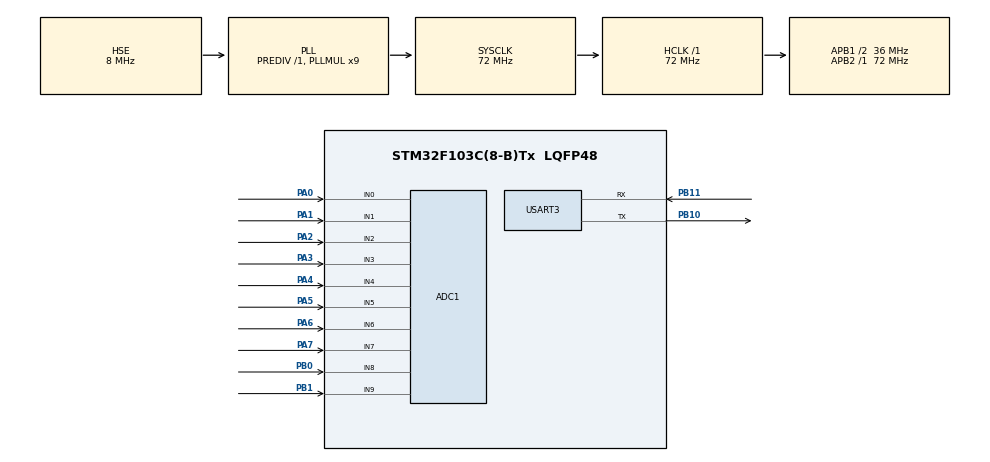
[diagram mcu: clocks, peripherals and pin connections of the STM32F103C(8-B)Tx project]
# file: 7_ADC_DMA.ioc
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Mcu.Family=STM32F1
NVIC.ADC1_2_IRQn=true\:0\:0\:false\:false\:true\:true\:true
ADC1.ContinuousConvMode=DISABLE
PB10.Mode=Asynchronous
SH.ADCx_IN2.0=ADC1_IN2,IN2
ADC1.SamplingTime-6\#ChannelRegularConversion=ADC_SAMPLETIME_1CYCLE_5
PB11.Signal=USART3_RX
ADC1.Channel-8\#ChannelRegularConversion=ADC_CHANNEL_8
RCC.SYSCLKSource=RCC_SYSCLKSOURCE_PLLCLK
ProjectManager.StackSize=0x400
PD1-OSC_OUT.Signal=RCC_OSC_OUT
ADC1.Channel-5\#ChannelRegularConversion=ADC_CHANNEL_5
ADC1.Channel-3\#ChannelRegularConversion=ADC_CHANNEL_3
RCC.HCLKFreq_Value=72000000
SH.ADCx_IN3.0=ADC1_IN3,IN3
RCC.APB2TimFreq_Value=72000000
Dma.ADC1.0.Direction=DMA_PERIPH_TO_MEMORY
ADC1.Channel-2\#ChannelRegularConversion=ADC_CHANNEL_2
Dma.ADC1.0.MemDataAlignment=DMA_MDATAALIGN_HALFWORD
RCC.AHBFreq_Value=72000000
ADC1.Channel-0\#ChannelRegularConversion=ADC_CHANNEL_0
RCC.PLLMUL=RCC_PLL_MUL9
ADC1.SamplingTime-4\#ChannelRegularConversion=ADC_SAMPLETIME_1CYCLE_5
ADC1.Channel-6\#ChannelRegularConversion=ADC_CHANNEL_6
ADC1.Rank-2\#ChannelRegularConversion=3
PA14.Mode=Serial_Wire
Dma.ADC1.0.PeriphInc=DMA_PINC_DISABLE
SH.ADCx_IN8.0=ADC1_IN8,IN8
SH.ADCx_IN0.0=ADC1_IN0,IN0
ADC1.SamplingTime-0\#ChannelRegularConversion=ADC_SAMPLETIME_1CYCLE_5
Mcu.Package=LQFP48
PA6.Signal=ADCx_IN6
PB1.Signal=ADCx_IN9
SH.ADCx_IN9.0=ADC1_IN9,IN9
SH.ADCx_IN1.0=ADC1_IN1,IN1
RCC.APB1TimFreq_Value=72000000
Dma.Request0=ADC1
ADC1.Rank-6\#ChannelRegularConversion=7
ADC1.SamplingTime-8\#ChannelRegularConversion=ADC_SAMPLETIME_1CYCLE_5
ADC1.Rank-4\#ChannelRegularConversion=5
PA3.Signal=ADCx_IN3
RCC.PLLSourceVirtual=RCC_PLLSOURCE_HSE
Dma.ADC1.0.Instance=DMA1_Channel1
ADC1.Rank-0\#ChannelRegularConversion=1
PD1-OSC_OUT.Mode=HSE-External-Oscillator
ADC1.Channel-4\#ChannelRegularConversion=ADC_CHANNEL_4
SH.ADCx_IN6.0=ADC1_IN6,IN6
ADC1.Rank-8\#ChannelRegularConversion=9
PD0-OSC_IN.Signal=RCC_OSC_IN
RCC.APB1CLKDivider=RCC_HCLK_DIV2
ADC1.SamplingTime-2\#ChannelRegularConversion=ADC_SAMPLETIME_1CYCLE_5
PA0-WKUP.Signal=ADCx_IN0
ADC1.Channel-7\#ChannelRegularConversion=ADC_CHANNEL_7
RCC.ADCPresc=RCC_ADCPCLK2_DIV6
PA13.Signal=SYS_JTMS-SWDIO
Dma.ADC1.0.PeriphDataAlignment=DMA_PDATAALIGN_HALFWORD
PB11.Mode=Asynchronous
ProjectManager.TargetToolchain=STM32CubeIDE
SH.ADCx_IN7.0=ADC1_IN7,IN7
Dma.ADC1.0.Mode=DMA_CIRCULAR
Dma.ADC1.0.Priority=DMA_PRIORITY_LOW
ADC1.Channel-1\#ChannelRegularConversion=ADC_CHANNEL_1
RCC.USBFreq_Value=72000000
PA1.Signal=ADCx_IN1
PD0-OSC_IN.Mode=HSE-External-Oscillator
PB10.Signal=USART3_TX
PA5.Signal=ADCx_IN5
board=custom
RCC.APB2Freq_Value=72000000
SH.ADCx_IN4.0=ADC1_IN4,IN4
ADC1.Rank-9\#ChannelRegularConversion=10
ADC1.NbrOfConversion=10
PA13.Mode=Serial_Wire
Mcu.Name=STM32F103C(8-B)Tx
PA2.Signal=ADCx_IN2
ADC1.Channel-9\#ChannelRegularConversion=ADC_CHANNEL_9
PA4.Signal=ADCx_IN4
ADC1.SamplingTime-1\#ChannelRegularConversion=ADC_SAMPLETIME_1CYCLE_5
RCC.SYSCLKFreq_VALUE=72000000
ADC1.master=1
ADC1.Rank-3\#ChannelRegularConversion=4
ADC1.SamplingTime-3\#ChannelRegularConversion=ADC_SAMPLETIME_1CYCLE_5
USART3.VirtualMode=VM_ASYNC
ADC1.Rank-1\#ChannelRegularConversion=2
PA14.Signal=SYS_JTCK-SWCLK
Dma.ADC1.0.MemInc=DMA_MINC_ENABLE
ProjectManager.HeapSize=0x200
ADC1.SamplingTime-5\#ChannelRegularConversion=ADC_SAMPLETIME_1CYCLE_5
SH.ADCx_IN5.0=ADC1_IN5,IN5
ADC1.Rank-7\#ChannelRegularConversion=8
NVIC.PriorityGroup=NVIC_PRIORITYGROUP_4
ADC1.NbrOfConversionFlag=1
ADC1.SamplingTime-9\#ChannelRegularConversion=ADC_SAMPLETIME_1CYCLE_5
ADC1.SamplingTime-7\#ChannelRegularConversion=ADC_SAMPLETIME_1CYCLE_5
NVIC.DMA1_Channel1_IRQn=true\:0\:0\:false\:false\:true\:false\:true
RCC.APB1Freq_Value=36000000
PB0.Signal=ADCx_IN8
ADC1.Rank-5\#ChannelRegularConversion=6
PA7.Signal=ADCx_IN7

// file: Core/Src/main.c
/* USER CODE BEGIN Header */
/**
  ******************************************************************************
  * @file           : main.c
  * @brief          : Main program body
  ******************************************************************************
  * @attention
  *
  * <h2><center>&copy; Copyright (c) 2021 STMicroelectronics.
  * All rights reserved.</center></h2>
  *
  * This software component is licensed by ST under BSD 3-Clause license,
  * the "License"; You may not use this file except in compliance with the
  * License. You may obtain a copy of the License at:
  *                        opensource.org/licenses/BSD-3-Clause
  *
  ******************************************************************************
  */
/*This project is using ADC and DMA to Read 10 channels*/
/* USER CODE END Header */
#include "main.h"

ADC_HandleTypeDef hadc1;
DMA_HandleTypeDef hdma_adc1;

UART_HandleTypeDef huart3;

void SystemClock_Config(void);
static void MX_GPIO_Init(void);
static void MX_DMA_Init(void);
static void MX_ADC1_Init(void);
static void MX_USART3_UART_Init(void);
/* USER CODE BEGIN PFP */
volatile uint16_t adcVal[10];
uint16_t Buff[4];
/* USER CODE END PFP */

int main(void)
{

  /* MCU Configuration--------------------------------------------------------*/

  /* Reset of all peripherals, Initializes the Flash interface and the Systick. */
  HAL_Init();

  /* Configure the system clock */
  SystemClock_Config();

  /* Initialize all configured peripherals */
  MX_GPIO_Init();
  MX_DMA_Init();
  MX_ADC1_Init();
  MX_USART3_UART_Init();

  /* Infinite loop */
  while (1)
  {

    /* USER CODE BEGIN 3 */
	  HAL_ADC_Start_DMA(&hadc1,(uint32_t*)adcVal,10);
	  HAL_Delay(1);
	  HAL_ADC_Stop_DMA(&hadc1);
	  for(uint8_t i = 0; i<10;i++)
		  {
			  HAL_UART_Transmit(&huart3, (uint8_t*)Buff, sprintf(Buff, "%d", adcVal[i]), 500);
			  if(i<9)
				  HAL_UART_Transmit(&huart3,",", 1, 500);
			  HAL_Delay(200);
		  }
		  HAL_UART_Transmit(&huart3,"\n", 2, 500);
		  HAL_Delay(200);
  }
  /* USER CODE END 3 */
}

void SystemClock_Config(void)
{
  RCC_OscInitTypeDef RCC_OscInitStruct = {0};
  RCC_ClkInitTypeDef RCC_ClkInitStruct = {0};
  RCC_PeriphCLKInitTypeDef PeriphClkInit = {0};

  /** Initializes the RCC Oscillators according to the specified parameters
  * in the RCC_OscInitTypeDef structure.
  */
  RCC_OscInitStruct.OscillatorType = RCC_OSCILLATORTYPE_HSE;
  RCC_OscInitStruct.HSEState = RCC_HSE_ON;
  RCC_OscInitStruct.HSEPredivValue = RCC_HSE_PREDIV_DIV1;
  RCC_OscInitStruct.HSIState = RCC_HSI_ON;
  RCC_OscInitStruct.PLL.PLLState = RCC_PLL_ON;
  RCC_OscInitStruct.PLL.PLLSource = RCC_PLLSOURCE_HSE;
  RCC_OscInitStruct.PLL.PLLMUL = RCC_PLL_MUL9;
  if (HAL_RCC_OscConfig(&RCC_OscInitStruct) != HAL_OK)
  {
    Error_Handler();
  }
  /** Initializes the CPU, AHB and APB buses clocks
  */
  RCC_ClkInitStruct.ClockType = RCC_CLOCKTYPE_HCLK|RCC_CLOCKTYPE_SYSCLK
                              |RCC_CLOCKTYPE_PCLK1|RCC_CLOCKTYPE_PCLK2;
  RCC_ClkInitStruct.SYSCLKSource = RCC_SYSCLKSOURCE_PLLCLK;
  RCC_ClkInitStruct.AHBCLKDivider = RCC_SYSCLK_DIV1;
  RCC_ClkInitStruct.APB1CLKDivider = RCC_HCLK_DIV2;
  RCC_ClkInitStruct.APB2CLKDivider = RCC_HCLK_DIV1;

  if (HAL_RCC_ClockConfig(&RCC_ClkInitStruct, FLASH_LATENCY_2) != HAL_OK)
  {
    Error_Handler();
  }
  PeriphClkInit.PeriphClockSelection = RCC_PERIPHCLK_ADC;
  PeriphClkInit.AdcClockSelection = RCC_ADCPCLK2_DIV6;
  if (HAL_RCCEx_PeriphCLKConfig(&PeriphClkInit) != HAL_OK)
  {
    Error_Handler();
  }
}

static void MX_ADC1_Init(void)
{

  ADC_ChannelConfTypeDef sConfig = {0};

  /** Common config
  */
  hadc1.Instance = ADC1;
  hadc1.Init.ScanConvMode = ADC_SCAN_ENABLE;
  hadc1.Init.ContinuousConvMode = DISABLE;
  hadc1.Init.DiscontinuousConvMode = DISABLE;
  hadc1.Init.ExternalTrigConv = ADC_SOFTWARE_START;
  hadc1.Init.DataAlign = ADC_DATAALIGN_RIGHT;
  hadc1.Init.NbrOfConversion = 10;
  if (HAL_ADC_Init(&hadc1) != HAL_OK)
  {
    Error_Handler();
  }
  /** Configure Regular Channel
  */
  sConfig.Channel = ADC_CHANNEL_0;
  sConfig.Rank = ADC_REGULAR_RANK_1;
  sConfig.SamplingTime = ADC_SAMPLETIME_1CYCLE_5;
  if (HAL_ADC_ConfigChannel(&hadc1, &sConfig) != HAL_OK)
  {
    Error_Handler();
  }
  /** Configure Regular Channel
  */
  sConfig.Channel = ADC_CHANNEL_1;
  sConfig.Rank = ADC_REGULAR_RANK_2;
  if (HAL_ADC_ConfigChannel(&hadc1, &sConfig) != HAL_OK)
  {
    Error_Handler();
  }
  /** Configure Regular Channel
  */
  sConfig.Channel = ADC_CHANNEL_2;
  sConfig.Rank = ADC_REGULAR_RANK_3;
  if (HAL_ADC_ConfigChannel(&hadc1, &sConfig) != HAL_OK)
  {
    Error_Handler();
  }
  /** Configure Regular Channel
  */
  sConfig.Channel = ADC_CHANNEL_3;
  sConfig.Rank = ADC_REGULAR_RANK_4;
  if (HAL_ADC_ConfigChannel(&hadc1, &sConfig) != HAL_OK)
  {
    Error_Handler();
  }
  /** Configure Regular Channel
  */
  sConfig.Channel = ADC_CHANNEL_4;
  sConfig.Rank = ADC_REGULAR_RANK_5;
  if (HAL_ADC_ConfigChannel(&hadc1, &sConfig) != HAL_OK)
  {
    Error_Handler();
  }
  /** Configure Regular Channel
  */
  sConfig.Channel = ADC_CHANNEL_5;
  sConfig.Rank = ADC_REGULAR_RANK_6;
  if (HAL_ADC_ConfigChannel(&hadc1, &sConfig) != HAL_OK)
  {
    Error_Handler();
  }
  /** Configure Regular Channel
  */
  sConfig.Channel = ADC_CHANNEL_6;
  sConfig.Rank = ADC_REGULAR_RANK_7;
  if (HAL_ADC_ConfigChannel(&hadc1, &sConfig) != HAL_OK)
  {
    Error_Handler();
  }
  /** Configure Regular Channel
  */
  sConfig.Channel = ADC_CHANNEL_7;
  sConfig.Rank = ADC_REGULAR_RANK_8;
  if (HAL_ADC_ConfigChannel(&hadc1, &sConfig) != HAL_OK)
  {
    Error_Handler();
  }
  /** Configure Regular Channel
  */
  sConfig.Channel = ADC_CHANNEL_8;
  sConfig.Rank = ADC_REGULAR_RANK_9;
  if (HAL_ADC_ConfigChannel(&hadc1, &sConfig) != HAL_OK)
  {
    Error_Handler();
  }
  /** Configure Regular Channel
  */
  sConfig.Channel = ADC_CHANNEL_9;
  sConfig.Rank = ADC_REGULAR_RANK_10;
  if (HAL_ADC_ConfigChannel(&hadc1, &sConfig) != HAL_OK)
  {
    Error_Handler();
  }

}

static void MX_USART3_UART_Init(void)
{

  huart3.Instance = USART3;
  huart3.Init.BaudRate = 115200;
  huart3.Init.WordLength = UART_WORDLENGTH_8B;
  huart3.Init.StopBits = UART_STOPBITS_1;
  huart3.Init.Parity = UART_PARITY_NONE;
  huart3.Init.Mode = UART_MODE_TX_RX;
  huart3.Init.HwFlowCtl = UART_HWCONTROL_NONE;
  huart3.Init.OverSampling = UART_OVERSAMPLING_16;
  if (HAL_UART_Init(&huart3) != HAL_OK)
  {
    Error_Handler();
  }

}

static void MX_DMA_Init(void)
{

  /* DMA controller clock enable */
  __HAL_RCC_DMA1_CLK_ENABLE();

  /* DMA interrupt init */
  /* DMA1_Channel1_IRQn interrupt configuration */
  HAL_NVIC_SetPriority(DMA1_Channel1_IRQn, 0, 0);
  HAL_NVIC_EnableIRQ(DMA1_Channel1_IRQn);

}

static void MX_GPIO_Init(void)
{

  /* GPIO Ports Clock Enable */
  __HAL_RCC_GPIOD_CLK_ENABLE();
  __HAL_RCC_GPIOA_CLK_ENABLE();
  __HAL_RCC_GPIOB_CLK_ENABLE();

}

void Error_Handler(void)
{
  __disable_irq();
  while (1)
  {
  }
}

/************************ (C) COPYRIGHT STMicroelectronics *****END OF FILE****/
